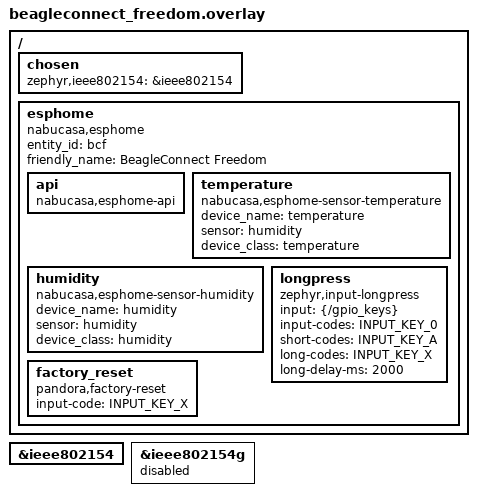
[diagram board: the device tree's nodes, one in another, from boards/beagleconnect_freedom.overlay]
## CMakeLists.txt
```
# SPDX-License-Identifier: Apache-2.0

cmake_minimum_required(VERSION 3.20.0)

find_package(Zephyr REQUIRED HINTS $ENV{ZEPHYR_BASE})
project(esphome)

target_sources(app
    PRIVATE
        src/main.c
)
```

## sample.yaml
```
common:
  harness: net
  tags:
    - net
  min_flash: 140
sample:
  description: Zephyr ESPHome Firmware example
  name: ESPHome Firmware
tests:
  sample.net.esphome:
    build_only: true
    platform_allow:
      - native_sim
      - nucleo_f429zi
    integration_platforms:
      - native_sim
  sample.net.esphome.ot:
    build_only: true
    extra_args: EXTRA_CONF_FILE=overlay-openthread.conf
    platform_allow:
      - zeus
      - cc1352p7_lp
      - beagleconnect_freedom
    integration_platforms:
      - zeus
```

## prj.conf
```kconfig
# Enable ESPHome support and it dependencies
CONFIG_PROTOBUF_C=y
CONFIG_ESPHOME=y
CONFIG_ESPHOME_INIT_PRIORITY=91
CONFIG_KERNEL_MEM_POOL=y
CONFIG_HEAP_MEM_POOL_SIZE=2048

# Enable and configure network
CONFIG_NET_SOCKETS=y
CONFIG_NETWORKING=y

CONFIG_NET_IPV6=y
CONFIG_NET_DHCPV6=y
CONFIG_NET_IPV4=y
CONFIG_NET_DHCPV4=y
CONFIG_NET_CONFIG_SETTINGS=y
CONFIG_NET_TCP=y
CONFIG_NET_IPV4_MAPPING_TO_IPV6=y
CONFIG_NET_CONNECTION_MANAGER=y

CONFIG_NET_HOSTNAME_ENABLE=y
CONFIG_NET_HOSTNAME_UNIQUE=n
CONFIG_NET_HOSTNAME="zephyr"

CONFIG_NET_PKT_RX_COUNT=8
CONFIG_NET_PKT_TX_COUNT=8

# Debug
CONFIG_LOG=y
CONFIG_PRINTK=y

CONFIG_SHELL=y
CONFIG_NET_SHELL=y

CONFIG_ESPHOME_RPC_LOG_LEVEL_DBG=y
```

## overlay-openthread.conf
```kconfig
# Kernel options
CONFIG_MAIN_STACK_SIZE=2560
CONFIG_INIT_STACKS=y

# Network options
CONFIG_NETWORKING=y
CONFIG_NET_L2_OPENTHREAD=y

# Openthread options
CONFIG_OPENTHREAD_DIAG=y
CONFIG_OPENTHREAD_DHCP6_CLIENT=y
CONFIG_OPENTHREAD_ENABLE_SERVICE=y
CONFIG_OPENTHREAD_SRP_CLIENT=y
CONFIG_OPENTHREAD_COAP=y
CONFIG_OPENTHREAD_SLAAC=y

CONFIG_MBEDTLS_HEAP_SIZE=15360

# Increase logging thread stack size due to Spinel backend needs
CONFIG_LOG_PROCESS_THREAD_STACK_SIZE=2048

CONFIG_OPENTHREAD_JOINER=y
CONFIG_OPENTHREAD_JOINER_AUTOSTART=y
CONFIG_OPENTHREAD_JOINER_PSKD="J01NME"

CONFIG_SHELL=y
CONFIG_OPENTHREAD_SHELL=y
```

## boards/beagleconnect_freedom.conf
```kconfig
# Needed to use / store settings in SPI NOR
CONFIG_SPI_NOR_SFDP_RUNTIME=y
CONFIG_NVS=n
CONFIG_ZMS=y

# Enable 2.4G
CONFIG_IEEE802154_CC13XX_CC26XX_SUB_GHZ=n
CONFIG_IEEE802154_CC13XX_CC26XX=y

CONFIG_SENSOR=y

# Required for factory reset
CONFIG_INPUT=y
CONFIG_SYSTEM_WORKQUEUE_STACK_SIZE=2048

# OTA
CONFIG_STREAM_FLASH=y
CONFIG_IMG_MANAGER=y
```

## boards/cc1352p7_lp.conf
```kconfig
CONFIG_LED=y

# Required for OpenThread Settings
CONFIG_NVS=y
CONFIG_SETTINGS_NVS=y

# Input
CONFIG_INPUT=y
#CONFIG_INPUT_LONGPRESS=y

# Reboot
CONFIG_REBOOT=y

# FIXME
# This workaround the following issue with joiner:
# Join failed [Security]
# CONFIG_OPENTHREAD_DEBUG=y
# CONFIG_OPENTHREAD_LOG_LEVEL_INFO=y

CONFIG_SYSTEM_WORKQUEUE_STACK_SIZE=2048
```

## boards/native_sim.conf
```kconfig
CONFIG_GPIO=y
CONFIG_GPIO_EMUL=y
CONFIG_HEAP_MEM_POOL_SIZE=4096

# Kernel options
CONFIG_MAIN_STACK_SIZE=2048
CONFIG_ENTROPY_GENERATOR=y
CONFIG_TEST_RANDOM_GENERATOR=y
CONFIG_INIT_STACKS=y

# Logging
CONFIG_NET_LOG=y
CONFIG_LOG=y
CONFIG_PRINTK=y

# Network buffers
CONFIG_NET_PKT_RX_COUNT=16
CONFIG_NET_PKT_TX_COUNT=16
CONFIG_NET_BUF_RX_COUNT=64
CONFIG_NET_BUF_TX_COUNT=64
CONFIG_NET_CONTEXT_NET_PKT_POOL=y

# IP address options
CONFIG_NET_IF_UNICAST_IPV6_ADDR_COUNT=3
CONFIG_NET_IF_MCAST_IPV6_ADDR_COUNT=4
CONFIG_NET_MAX_CONTEXTS=10

# Network application options and configuration
CONFIG_NET_CONFIG_NEED_IPV6=y
CONFIG_NET_CONFIG_MY_IPV6_ADDR="2001:db8::1"
CONFIG_NET_CONFIG_PEER_IPV6_ADDR="2001:db8::2"
CONFIG_NET_CONFIG_NEED_IPV4=y
CONFIG_NET_CONFIG_MY_IPV4_ADDR="192.0.2.1"
CONFIG_NET_CONFIG_PEER_IPV4_ADDR="192.0.2.2"

# Number of socket descriptors might need adjusting
# if there are more than 1 handlers defined.
CONFIG_ZVFS_OPEN_MAX=12
```

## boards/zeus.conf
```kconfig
# Needed to use / store settings in SPI NOR
CONFIG_SPI_NOR_SFDP_RUNTIME=y
CONFIG_NVS=n
CONFIG_ZMS=y

# Enable 2.4G
CONFIG_IEEE802154_CC13XX_CC26XX_SUB_GHZ=n
CONFIG_IEEE802154_CC13XX_CC26XX=y

# Required for factory reset
CONFIG_INPUT=y
CONFIG_SYSTEM_WORKQUEUE_STACK_SIZE=2048

# OTA
CONFIG_STREAM_FLASH=y
CONFIG_IMG_MANAGER=y
```

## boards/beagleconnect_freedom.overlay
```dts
/*
 * Copyright (c) 2025 Alexandre Bailon
 *
 * SPDX-License-Identifier: Apache-2.0
 */

/ {
	chosen {
		zephyr,ieee802154 = &ieee802154;
	};

        esphome {
                compatible = "nabucasa,esphome";
                entity_id = "bcf";
                friendly_name = "BeagleConnect Freedom";
                status = "okay";

		api {
			compatible = "nabucasa,esphome-api";
			status = "okay";
		};

		temperature {
			compatible = "nabucasa,esphome-sensor-temperature";
			device_name = "temperature";
			sensor = <&humidity>;
			device_class = "temperature";
		};

		humidity {
			compatible = "nabucasa,esphome-sensor-humidity";
			device_name = "humidity";
			sensor = <&humidity>;
			device_class = "humidity";
		};

		longpress {
			input = <&{/gpio_keys}>;
			compatible = "zephyr,input-longpress";
			input-codes = <INPUT_KEY_0>;
			short-codes = <INPUT_KEY_A>;
			long-codes = <INPUT_KEY_X>;
			long-delay-ms = <2000>;
		};

		factory_reset {
			compatible = "pandora,factory-reset";
			input-code = <INPUT_KEY_X>;
		};
        };
};

&ieee802154 {
	status = "okay";
};

&ieee802154g {
	status = "disabled";
};
```

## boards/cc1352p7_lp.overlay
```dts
#include <zephyr/dt-bindings/input/input-event-codes.h>

/ {
	esphome {
		compatible = "nabucasa,esphome";
		entity_id = "zephyr_esphome";
		friendly_name = " Zephyr ESPHOME cc1352p7_lp";
		status = "okay";

		api {
			compatible = "nabucasa,esphome-api";
			password = "mypassword";
			status = "okay";
		};

		gpio-output {
			gpio-output-7 {
				compatible = "pandora,switch-gpio";
				component-name = "GPIO LED 7";
				gpios = <&gpio0 7 GPIO_ACTIVE_HIGH>;
				status = "okay";
			};
		};

		longpress {
			input = <&{/keys}>;
			compatible = "zephyr,input-longpress";
			input-codes = <INPUT_KEY_0>;
			short-codes = <INPUT_KEY_A>;
			long-codes = <INPUT_KEY_X>;
			long-delay-ms = <2000>;
		};

		factory_reset {
			compatible = "pandora,factory-reset";
			input-code = <INPUT_KEY_X>;
		};
	};
};

&uart0 {
	zephyr,pm-device-runtime-auto;
};
```

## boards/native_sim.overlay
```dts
/ {
        esphome {
                compatible = "nabucasa,esphome";
                entity_id = "zephyr_esphome";
                friendly_name = " Zephyr ESPHOME sample device";
                status = "okay";

                api {
                        compatible = "nabucasa,esphome-api";
                        password = "mypassword";
                        status = "okay";
                };

                ha-btn-1 {
                        compatible = "nabucasa,esphome-button-template";
                        device_name = "Button 1";
                        on_press = "ha_btn_1_on_push_cb";
                        status = "okay";
                };

                ha-btn-2 {
                        compatible = "nabucasa,esphome-button-template";
                        device_name = "Button 2";
                        on_press = "ha_btn_2_on_push_cb";
                        status = "okay";
                };

                timestamp {
                        compatible = "nabucasa,esphome-sensor-timestamp";
                        device_class = "timestamp";
                        device_name = "Timestamp";
                        status = "okay";
                };

                gpio-switch-0 {
                        compatible = "pandora,switch-gpio";
                        component-name = "GPIO LED 0";
                        gpios = <&gpio0 0 GPIO_ACTIVE_HIGH>;
                        status = "okay";
                };
        };
};
```

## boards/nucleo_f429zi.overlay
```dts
/ {
        esphome {
                compatible = "nabucasa,esphome";
                entity_id = "zephyr_esphome";
                friendly_name = " Zephyr ESPHOME sample device";
                status = "okay";

                api {
                        compatible = "nabucasa,esphome-api";
                        password = "mypassword";
                        status = "okay";
                };

                gpio-output {
                        gpio-output-7 {
                                compatible = "pandora,switch-gpio";
                                component-name = "GPIO LED 7";
                                gpios = <&gpiob 7 GPIO_ACTIVE_HIGH>;
                                status = "okay";
                        };
                };

                buttons {
                        ha-btn-1 {
                                compatible = "nabucasa,esphome-button";
                                device_name = "Button 1";
                                on_push = "ha_btn_1_on_push_cb";
                                status = "okay";
                        };

                        ha-btn-2 {
                                compatible = "nabucasa,esphome-button";
                                device_name = "Button 2";
                                on_push = "ha_btn_2_on_push_cb";
                                status = "okay";
                        };
                };
        };
};
```

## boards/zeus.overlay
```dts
/*
 * Copyright (c) 2026 Alexandre Bailon
 *
 * SPDX-License-Identifier: Apache-2.0
 */

/ {
	chosen {
		zephyr,ieee802154 = &ieee802154;
	};

        esphome {
                compatible = "nabucasa,esphome";
                entity_id = "zeus";
                friendly_name = "Zeus power switch";
                status = "okay";

		api {
			compatible = "nabucasa,esphome-api";
			status = "okay";
		};

		hbridge_switch: switch_0 {
			compatible = "pandora,switch-hbridge";
			component-name = "Bistable relay";
			on-gpios = <&gpio0 21 GPIO_ACTIVE_HIGH>;
			off-gpios = <&gpio0 22 GPIO_ACTIVE_HIGH>;
			wait-time = <1000>;
			status = "okay";
		};

		input_switch: binary_sensor_0 {
			compatible = "pandora,binary-sensor-gpio";
			component-name = "Switch";
			gpios = <&gpio0 14 GPIO_ACTIVE_HIGH>;
			status = "okay";
		};

		pipelines {
			input_switch_toggle_hbridge_switch {
				compatible = "pandora,pipeline";
				component-name = "Control relay using switch";
				binary-sensor-on-state = <&input_switch>;
				switch-toggle = <&hbridge_switch>;
			};
		};

		longpress {
			input = <&{/keys}>;
			compatible = "zephyr,input-longpress";
			input-codes = <INPUT_KEY_0>;
			short-codes = <INPUT_KEY_A>;
			long-codes = <INPUT_KEY_X>;
			long-delay-ms = <2000>;
		};

		factory_reset {
			compatible = "pandora,factory-reset";
			input-code = <INPUT_KEY_X>;
		};
        };
};
```

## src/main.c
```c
/*
 * Copyright (c) 2024 Alexandre Bailon
 *
 * SPDX-License-Identifier: Apache-2.0
 */

#include <zephyr/logging/log.h>
LOG_MODULE_REGISTER(ESPHOME_SAMPLE);

int ha_btn_1_on_push_cb(const struct device *dev)
{
	ARG_UNUSED(dev);

	LOG_INF("on_push: ha-btn-1\n");

	return 0;
}

int ha_btn_2_on_push_cb(const struct device *dev)
{
	ARG_UNUSED(dev);

	LOG_INF("on_push: ha-btn-2\n");

	return 0;
}

int main(void)
{
	return 0;
}
```
